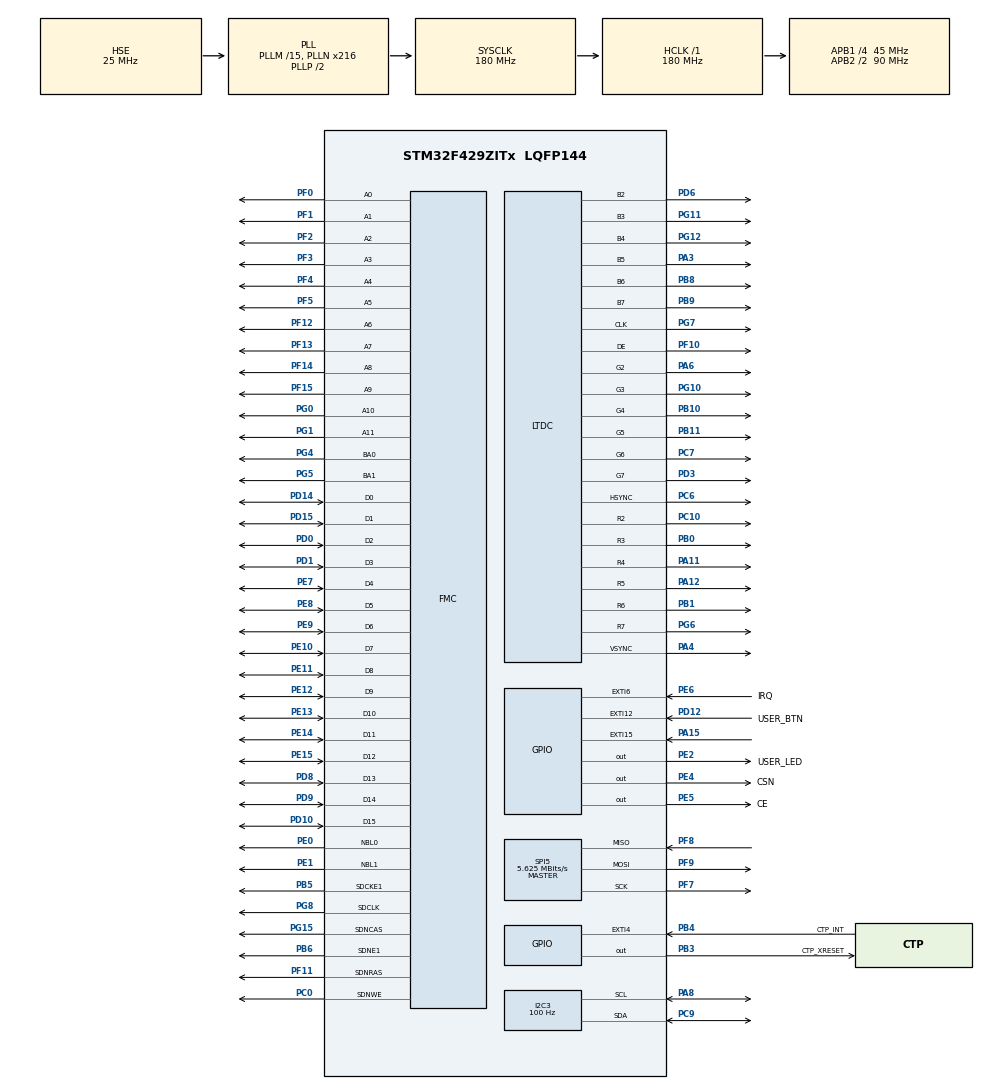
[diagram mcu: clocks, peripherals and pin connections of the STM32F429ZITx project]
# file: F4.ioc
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STMicroelectronics.X-CUBE-TOUCHGFX.4.14.0.tgfx_address1=0xd0000000
SH.FMC_D7_DA7.0=FMC_D7,sd-16b-d1
STMicroelectronics.X-CUBE-TOUCHGFX.4.14.0.tgfx_address2=0xC003FC00
PD12.GPIO_Label=USER_BTN
VP_SYS_VS_tim6.Mode=TIM6
FMC.RCDDelay1=2
FMC.SDClockPeriod1=FMC_SDRAM_CLOCK_PERIOD_2
SH.FMC_A0.0=FMC_A0,12b-sda1
PB10.Mode=RGB666
VP_ADC1_TempSens_Input.Mode=IN-TempSens
FREERTOS.configUSE_DAEMON_TASK_STARTUP_HOOK=0
NVIC.TIM6_DAC_IRQn=true\:0\:0\:false\:false\:true\:false\:true\:true
PG8.Signal=FMC_SDCLK
PG4.Signal=FMC_A14_BA0
PG0.Signal=FMC_A10
FMC.LoadToActiveDelay1=2
SH.FMC_D5_DA5.0=FMC_D5,sd-16b-d1
PG6.Mode=RGB666
PE6.GPIO_Label=IRQ
LTDC.Red=0
RCC.SYSCLKSource=RCC_SYSCLKSOURCE_PLLCLK
SH.FMC_A15_BA1.0=FMC_BA1,FourSdramBanks1
SH.FMC_D9_DA9.0=FMC_D9,sd-16b-d1
FREERTOS.configENABLE_FPU=0
FREERTOS.INCLUDE_pcTaskGetTaskName=0
I2C3.AddressingMode=I2C_ADDRESSINGMODE_7BIT
PA4.Mode=RGB666
PF7.Signal=SPI5_SCK
NVIC.DMA2D_IRQn=true\:5\:0\:true\:false\:true\:true\:true\:true
SH.FMC_SDNWE.0=FMC_SDNWE,12b-sda1
PB3.PinState=GPIO_PIN_SET
SH.FMC_D11_DA11.0=FMC_D11,sd-16b-d1
RCC.APB2TimFreq_Value=180000000
PB6.Signal=FMC_SDNE1
PC7.Signal=LTDC_G6
PH1/OSC_OUT.Signal=RCC_OSC_OUT
PB6.Mode=SdramChipSelect2_1
PD0.Signal=FMC_D2_DA2
PD8.Signal=FMC_D13_DA13
PE5.Signal=GPIO_Output
PE1.Signal=FMC_NBL1
FREERTOS.configMINIMAL_STACK_SIZE=128
I2C3.Analog_Filter=I2C_ANALOGFILTER_ENABLE
NVIC.EXTI15_10_IRQn=true\:0\:0\:false\:false\:true\:true\:true\:true
FMC.SelfRefreshTime1=4
LTDC.PixelFormat_L0=LTDC_PIXEL_FORMAT_RGB565
FREERTOS.INCLUDE_xQueueGetMutexHolder=0
PE9.Signal=FMC_D6_DA6
SH.FMC_A2.0=FMC_A2,12b-sda1
FREERTOS.HEAP_NUMBER=4
PE4.GPIO_Label=CSN
PC9.Mode=I2C
PE2.Signal=GPIO_Output
PF8.Mode=Full_Duplex_Master
PA8.Signal=I2C3_SCL
SH.FMC_D1_DA1.0=FMC_D1,sd-16b-d1
PF3.Signal=FMC_A3
VP_FREERTOS_VS_CMSIS_V1.Mode=CMSIS_V1
FMC.WriteProtection1=FMC_SDRAM_WRITE_PROTECTION_DISABLE
PD3.Mode=RGB666
PE10.Signal=FMC_D7_DA7
LTDC.HSync=1
ADC1.SamplingTime-0\#ChannelRegularConversion=ADC_SAMPLETIME_56CYCLES
Mcu.Package=LQFP144
PB9.Signal=LTDC_B7
PB1.Signal=LTDC_R6
FREERTOS.configUSE_NEWLIB_REENTRANT=0
NVIC.TimeBase=TIM6_DAC_IRQn
FREERTOS.INCLUDE_vTaskSuspend=1
PD12.Signal=GPXTI12
I2C3.NoStretchMode=I2C_NOSTRETCH_DISABLE
STMicroelectronics.X-CUBE-TOUCHGFX.4.14.0.tgfx_vsync=vsync_ltdc
LTDC.Green=0
NVIC.TimeBaseIP=TIM6
FREERTOS.copyHeapFile=1
FMC.WriteRecoveryTime1=3
SH.FMC_A1.0=FMC_A1,12b-sda1
FREERTOS.INCLUDE_vTaskPrioritySet=1
SPI5.CalculateBaudRate=5.625 MBits/s
RCC.APB2CLKDivider=RCC_HCLK_DIV2
SH.FMC_SDCLK.0=FMC_SDCLK,12b-sda1
LTDC.VSync=5
PF14.Signal=FMC_A8
RCC.APB1TimFreq_Value=90000000
FREERTOS.configGENERATE_RUN_TIME_STATS=0
VP_DMA2D_VS_DMA2D.Mode=DMA2D_Activate
PF10.Mode=RGB666
FMC.RowCycleDelay1=7
PD15.Signal=FMC_D1_DA1
SH.FMC_D3_DA3.0=FMC_D3,sd-16b-d1
SPI5.VirtualType=VM_MASTER
PG12.Signal=LTDC_B4
STMicroelectronics.X-CUBE-TOUCHGFX.4.14.0.tgfx_display_interface=disp_ltdc
NVIC.EXTI4_IRQn=true\:0\:0\:false\:false\:true\:false\:true\:true
SH.FMC_A4.0=FMC_A4,12b-sda1
FREERTOS.configIDLE_SHOULD_YIELD=1
FREERTOS.Tasks01=defaultTask,0,4096,StartDefaultTask,Default,NULL,Dynamic,NULL,NULL;ComunicationTas,0,128,StartComunicationTask,Default,NULL,Dynamic,NULL,NULL
ADC1.Rank-0\#ChannelRegularConversion=1
I2C3.OwnAddress=0
FREERTOS.INCLUDE_xTaskGetCurrentTaskHandle=0
DMA2D.AlphaModeForeground=DMA2D_NO_MODIF_ALPHA
PG5.Signal=FMC_A15_BA1
FREERTOS.configLIBRARY_LOWEST_INTERRUPT_PRIORITY=15
SH.FMC_D10_DA10.0=FMC_D10,sd-16b-d1
FREERTOS.INCLUDE_vTaskDelayUntil=0
FREERTOS.configCHECK_FOR_STACK_OVERFLOW=2
PD3.Signal=LTDC_G7
PC6.Signal=LTDC_HSYNC
PD1.Signal=FMC_D3_DA3
PC0.Signal=FMC_SDNWE
RCC.APB1CLKDivider=RCC_HCLK_DIV4
PD6.Mode=RGB666
PG10.Signal=LTDC_G3
DMA2D.InputOffsetForeground=0
LTDC.ImageWidth_L0=480
PD10.Signal=FMC_D15_DA15
PA3.Mode=RGB666
SH.FMC_A3.0=FMC_A3,12b-sda1
FMC.CASLatency1=FMC_SDRAM_CAS_LATENCY_3
PB11.Mode=RGB666
FREERTOS.configMAX_PRIORITIES=7
SH.FMC_D15_DA15.0=FMC_D15,sd-16b-d1
PC6.Mode=RGB666
FMC.SDBank1=FMC_SDRAM_BANK2
PB10.Signal=LTDC_G4
FREERTOS.configUSE_POSIX_ERRNO=0
FREERTOS.MEMORY_ALLOCATION=2
FMC.ReadBurst1=FMC_SDRAM_RBURST_DISABLE
SH.FMC_A6.0=FMC_A6,12b-sda1
PE14.Signal=FMC_D11_DA11
LTDC.Blue_L0=0
PE15.Signal=FMC_D12_DA12
PB4.GPIO_Label=CTP_INT
PE8.Signal=FMC_D5_DA5
I2C3.DualAddressMode=I2C_DUALADDRESS_DISABLE
FREERTOS.configUSE_CO_ROUTINES=0
FREERTOS.configUSE_MUTEXES=1
FREERTOS.INCLUDE_xEventGroupSetBitFromISR=0
PF13.Signal=FMC_A7
FREERTOS.configMAX_CO_ROUTINE_PRIORITIES=2
PA13.Mode=Serial_Wire
SH.FMC_SDNCAS.0=FMC_SDNCAS,12b-sda1
FREERTOS.INCLUDE_xTaskResumeFromISR=1
STMicroelectronics.X-CUBE-TOUCHGFX.4.14.0.tgfx_hardware_accelerator=dma_2d
FREERTOS.INCLUDE_uxTaskGetStackHighWaterMark2=0
PA4.Signal=LTDC_VSYNC
FREERTOS.configLIBRARY_MAX_SYSCALL_INTERRUPT_PRIORITY=5
PB5.Signal=FMC_SDCKE1
ADC1.master=1
FREERTOS.configUSE_COUNTING_SEMAPHORES=1
PE5.GPIO_Label=CE
SH.FMC_A5.0=FMC_A5,12b-sda1
PG11.Mode=RGB666
LTDC.Alpha_L0=255
PA11.Signal=LTDC_R4
ProjectManager.HeapSize=0x200
PB1.Mode=RGB666
FREERTOS.configUSE_RECURSIVE_MUTEXES=1
PF9.Signal=SPI5_MOSI
NVIC.PriorityGroup=NVIC_PRIORITYGROUP_4
PB8.Mode=RGB666
NVIC.I2C3_ER_IRQn=true\:5\:0\:true\:false\:true\:false\:true\:true
PA8.Mode=I2C
PF4.Signal=FMC_A4
PB0.Signal=LTDC_R3
LTDC.Alpha0_L0=0
Mcu.Family=STM32F4
STMicroelectronics.X-CUBE-TOUCHGFX.4.14.0.ApplicationCcGraphicsJjApplication=TouchGFXOoGenerator
LTDC.BlendingFactor1_L0=LTDC_BLENDING_FACTOR1_CA
PA6.Mode=RGB666
SH.FMC_A8.0=FMC_A8,12b-sda1
RCC.CortexFreq_Value=180000000
PG6.Signal=LTDC_R7
SH.FMC_D14_DA14.0=FMC_D14,sd-16b-d1
LTDC.HBP=42
PC10.Signal=LTDC_R2
SH.FMC_NBL0.0=FMC_NBL0,Sd2ByteEnable1
SH.FMC_D6_DA6.0=FMC_D6,sd-16b-d1
PA11.Mode=RGB666
FREERTOS.configTICK_RATE_HZ=1000
SH.FMC_A14_BA0.0=FMC_BA0,FourSdramBanks1
SH.FMC_A11.0=FMC_A11,12b-sda1
PB11.Signal=LTDC_G5
FREERTOS.configUSE_TASK_NOTIFICATIONS=1
LTDC.PCPolarity=LTDC_PCPOLARITY_IPC
VP_STMicroelectronics.X-CUBE-TOUCHGFX_VS_GraphicsJjApplication_4.14.0.Mode=GraphicsJjApplication
PG11.Signal=LTDC_B3
PG15.Signal=FMC_SDNCAS
ProjectManager.StackSize=0x400
STMicroelectronics.X-CUBE-TOUCHGFX.4.14.0.tgfx_buffering_strategy=Single
SH.FMC_A7.0=FMC_A7,12b-sda1
PA12.Signal=LTDC_R5
LTDC.Blue=0
FREERTOS.configUSE_STATS_FORMATTING_FUNCTIONS=0
PH0/OSC_IN.Mode=HSE-External-Oscillator
RCC.HCLKFreq_Value=180000000
SH.FMC_NBL1.0=FMC_NBL1,Sd2ByteEnable1
LTDC.WindowX1_L0=480
PF12.Signal=FMC_A6
FREERTOS.configUSE_MALLOC_FAILED_HOOK=1
FREERTOS.configQUEUE_REGISTRY_SIZE=8
SH.FMC_A10.0=FMC_A10,12b-sda1
RCC.AHBFreq_Value=180000000
FREERTOS.configUSE_PREEMPTION=1
ADC1.Channel-0\#ChannelRegularConversion=ADC_CHANNEL_TEMPSENSOR
RCC.HSE_VALUE=25000000
FREERTOS.configUSE_TIMERS=0
SH.FMC_D8_DA8.0=FMC_D8,sd-16b-d1
FMC.ExitSelfRefreshDelay1=7
FMC.RPDelay1=2
FREERTOS.configENABLE_BACKWARD_COMPATIBILITY=1
SH.FMC_D2_DA2.0=FMC_D2,sd-16b-d1
LTDC.VBP=10
NVIC.I2C3_EV_IRQn=true\:5\:0\:true\:false\:true\:false\:true\:true
PF9.Mode=Full_Duplex_Master
PE13.Signal=FMC_D10_DA10
PA14.Mode=Serial_Wire
PF11.Signal=FMC_SDNRAS
PB5.Mode=SdramChipSelect2_1
DMA2D.BytesSwap=DMA2D_BYTES_REGULAR
LTDC.Red_L0=0
LTDC.HFP=8
LTDC.BlendingFactor2_L0=LTDC_BLENDING_FACTOR2_CA
FREERTOS.INCLUDE_vTaskCleanUpResources=0
FMC.ReadPipeDelay1=FMC_SDRAM_RPIPE_DELAY_1
FMC.ReadPipeDelay2=FMC_SDRAM_RPIPE_DELAY_1
DMA2D.InputColorModeForeground=DMA2D_INPUT_ARGB8888
SH.FMC_SDNRAS.0=FMC_SDNRAS,12b-sda1
DMA2D.ColorMode=DMA2D_OUTPUT_ARGB8888
LTDC.ActiveW=480
PH1/OSC_OUT.Mode=HSE-External-Oscillator
PE4.Signal=GPIO_Output
FREERTOS.configTOTAL_HEAP_SIZE=32768
DMA2D.InputAlphaForeground=0
SPI5.BaudRatePrescaler=SPI_BAUDRATEPRESCALER_16
PA6.Signal=LTDC_G2
FREERTOS.INCLUDE_xTaskAbortDelay=0
SH.FMC_D0_DA0.0=FMC_D0,sd-16b-d1
DMA2D.OutputOffset=0
SH.FMC_A9.0=FMC_A9,12b-sda1
PA15.Signal=GPXTI15
PF8.Signal=SPI5_MISO
SH.FMC_D4_DA4.0=FMC_D4,sd-16b-d1
RCC.PLLSAIN=60
PF5.Signal=FMC_A5
FREERTOS.configUSE_TICK_HOOK=0
PF0.Signal=FMC_A0
LTDC.VSPolarity=LTDC_VSPOLARITY_AL
PE7.Signal=FMC_D4_DA4
FREERTOS.configMAX_TASK_NAME_LEN=16
PD6.Signal=LTDC_B2
PE2.GPIO_Label=USER_LED
DMA2D.LineOffsetMode=DMA2D_LOM_PIXELS
PB4.Signal=GPXTI4
PA3.Signal=LTDC_B5
PB3.GPIO_Label=CTP_XRESET
RCC.PLLSourceVirtual=RCC_PLLSOURCE_HSE
I2C3.I2C_Mode=I2C_Standard
NVIC.LTDC_IRQn=true\:5\:0\:true\:false\:true\:true\:true\:true
LTDC.FBStartAdress_L0=0xd0000000
LTDC.VFP=1
LTDC.HSPolarity=LTDC_HSPOLARITY_AL
STMicroelectronics.X-CUBE-TOUCHGFX.4.14.0.tgfx_location=By Address
LTDC.WindowY1_L0=272
PG7.Signal=LTDC_CLK
PG1.Signal=FMC_A11
FREERTOS.configUSE_TICKLESS_IDLE=0
I2C3.ClockSpeed=100
PC10.Mode=RGB666
PG10.Mode=RGB666
PD9.Signal=FMC_D14_DA14
FREERTOS.INCLUDE_vTaskDelay=1
FREERTOS.configUSE_APPLICATION_TASK_TAG=1
SPI5.Mode=SPI_MODE_MASTER
FREERTOS.INCLUDE_uxTaskGetStackHighWaterMark=0
PA13.Signal=SYS_JTMS-SWDIO
FREERTOS.configUSE_IDLE_HOOK=1
PF7.Mode=Full_Duplex_Master
FREERTOS.INCLUDE_vTaskDelete=1
I2C3.GeneralCallMode=I2C_GENERALCALL_DISABLE
I2C3.I2C_Coeff_DF=0
FREERTOS.configRECORD_STACK_HIGH_ADDRESS=0
ProjectManager.TargetToolchain=STM32CubeIDE
FREERTOS.configUSE_TRACE_FACILITY=0
SH.FMC_D13_DA13.0=FMC_D13,sd-16b-d1
LTDC.ActiveH=272
PB9.Mode=RGB666
PF2.Signal=FMC_A2
PE11.Signal=FMC_D8_DA8
PG7.Mode=RGB666
PB0.Mode=RGB666
board=custom
PG12.Mode=RGB666
RCC.VCOOutputFreq_Value=360000000
FREERTOS.INCLUDE_eTaskGetState=0
PH0/OSC_IN.Signal=RCC_OSC_IN
RCC.APB2Freq_Value=90000000
LTDC.Layers=0
PF10.Signal=LTDC_DE
SH.FMC_D12_DA12.0=FMC_D12,sd-16b-d1
PF15.Signal=FMC_A9
PF1.Signal=FMC_A1
PE6.Signal=GPXTI6
FREERTOS.INCLUDE_uxTaskPriorityGet=1
Mcu.Name=STM32F429ZITx
PE0.Signal=FMC_NBL0
PE12.Signal=FMC_D9_DA9
FREERTOS.INCLUDE_xSemaphoreGetMutexHolder=0
PD14.Signal=FMC_D0_DA0
LTDC.WindowY0_L0=0
RCC.48MHZClocksFreq_Value=90000000
PB3.Signal=GPIO_Output
RCC.SYSCLKFreq_VALUE=180000000
PA12.Mode=RGB666
LTDC.WindowX0_L0=0
LTDC.Green_L0=0
PA14.Signal=SYS_JTCK-SWCLK
FREERTOS.INCLUDE_xTaskGetHandle=0
LTDC.DEPolarity=LTDC_DEPOLARITY_AL
RCC.HSI_VALUE=16000000
ADC1.NbrOfConversionFlag=1
RCC.PLLM=15
RCC.PLLN=216
PB8.Signal=LTDC_B6
PC9.Signal=I2C3_SDA
PC7.Mode=RGB666
RCC.APB1Freq_Value=45000000
VP_CRC_VS_CRC.Mode=CRC_Activate
LTDC.ImageHeight_L0=272
DMA2D.Mode=DMA2D_M2M
SPI5.Direction=SPI_DIRECTION_2LINES

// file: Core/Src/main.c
/* USER CODE BEGIN Header */
/**
  ******************************************************************************
  * @file           : main.c
  * @brief          : Main program body
  ******************************************************************************
  * @attention
  *
  * <h2><center>&copy; Copyright (c) 2020 STMicroelectronics.
  * All rights reserved.</center></h2>
  *
  * This software component is licensed by ST under Ultimate Liberty license
  * SLA0044, the "License"; You may not use this file except in compliance with
  * the License. You may obtain a copy of the License at:
  *                             www.st.com/SLA0044
  *
  ******************************************************************************
  */
/* USER CODE END Header */
#include "main.h"
#include "cmsis_os.h"
#include "app_touchgfx.h"

/* USER CODE BEGIN Includes */
#include "FreeRTOS.h"
#include "queue.h"
#include "task.h"
#include "nRF24.h"
#include "nRF24_Defs.h"
/* USER CODE END Includes */

/* USER CODE BEGIN PD */
#define REFRESH_COUNT        1386

#define SDRAM_TIMEOUT                            ((uint32_t)0xFFFF)
#define SDRAM_MODEREG_BURST_LENGTH_1             ((uint16_t)0x0000)
#define SDRAM_MODEREG_BURST_LENGTH_2             ((uint16_t)0x0001)
#define SDRAM_MODEREG_BURST_LENGTH_4             ((uint16_t)0x0002)
#define SDRAM_MODEREG_BURST_LENGTH_8             ((uint16_t)0x0004)
#define SDRAM_MODEREG_BURST_TYPE_SEQUENTIAL      ((uint16_t)0x0000)
#define SDRAM_MODEREG_BURST_TYPE_INTERLEAVED     ((uint16_t)0x0008)
#define SDRAM_MODEREG_CAS_LATENCY_2              ((uint16_t)0x0020)
#define SDRAM_MODEREG_CAS_LATENCY_3              ((uint16_t)0x0030)
#define SDRAM_MODEREG_OPERATING_MODE_STANDARD    ((uint16_t)0x0000)
#define SDRAM_MODEREG_WRITEBURST_MODE_PROGRAMMED ((uint16_t)0x0000)
#define SDRAM_MODEREG_WRITEBURST_MODE_SINGLE     ((uint16_t)0x0200)

static FMC_SDRAM_CommandTypeDef Command;
/* USER CODE END PD */

ADC_HandleTypeDef hadc1;

CRC_HandleTypeDef hcrc;

DMA2D_HandleTypeDef hdma2d;

I2C_HandleTypeDef hi2c3;

LTDC_HandleTypeDef hltdc;

SPI_HandleTypeDef hspi5;

SDRAM_HandleTypeDef hsdram1;

osThreadId defaultTaskHandle;
osThreadId ComunicationTasHandle;
/* USER CODE BEGIN PV */
volatile uint8_t nrf24_rx_flag, nrf24_tx_flag, nrf24_mr_flag;
uint8_t Nrf24_Message[NRF24_PAYLOAD_SIZE];
uint8_t Message[32];
uint8_t MessageLength;
/* USER CODE END PV */

void SystemClock_Config(void);
static void MX_GPIO_Init(void);
static void MX_LTDC_Init(void);
static void MX_CRC_Init(void);
static void MX_DMA2D_Init(void);
static void MX_FMC_Init(void);
static void MX_I2C3_Init(void);
static void MX_ADC1_Init(void);
static void MX_SPI5_Init(void);
void StartDefaultTask(void const * argument);
void StartComunicationTask(void const * argument);

int main(void)
{

  /* MCU Configuration--------------------------------------------------------*/

  /* Reset of all peripherals, Initializes the Flash interface and the Systick. */
  HAL_Init();

  /* Configure the system clock */
  SystemClock_Config();

  /* Initialize all configured peripherals */
  MX_GPIO_Init();
  MX_LTDC_Init();
  MX_CRC_Init();
  MX_DMA2D_Init();
  MX_FMC_Init();
  MX_I2C3_Init();
  MX_TouchGFX_Init();
  MX_ADC1_Init();
  MX_SPI5_Init();
  //MX_TouchGFX_Init();
  /* USER CODE BEGIN 2 */
  //nRF24_Init(&hspi5);
  //nRF24_SetRXAddress(0, "TX");
  //nRF24_SetTXAddress("RX");
  //nRF24_RX_Mode();
  /* USER CODE END 2 */

  /* Create the thread(s) */
  /* definition and creation of defaultTask */
  osThreadDef(defaultTask, StartDefaultTask, osPriorityNormal, 0, 4096);
  defaultTaskHandle = osThreadCreate(osThread(defaultTask), NULL);

  /* definition and creation of ComunicationTas */
  osThreadDef(ComunicationTas, StartComunicationTask, osPriorityNormal, 0, 128);
  ComunicationTasHandle = osThreadCreate(osThread(ComunicationTas), NULL);

  /* Start scheduler */
  osKernelStart();

  /* We should never get here as control is now taken by the scheduler */
  /* Infinite loop */
  while (1)
  {

  }
}

void SystemClock_Config(void)
{
  RCC_OscInitTypeDef RCC_OscInitStruct = {0};
  RCC_ClkInitTypeDef RCC_ClkInitStruct = {0};
  RCC_PeriphCLKInitTypeDef PeriphClkInitStruct = {0};

  /** Configure the main internal regulator output voltage
  */
  __HAL_RCC_PWR_CLK_ENABLE();
  __HAL_PWR_VOLTAGESCALING_CONFIG(PWR_REGULATOR_VOLTAGE_SCALE1);
  /** Initializes the RCC Oscillators according to the specified parameters
  * in the RCC_OscInitTypeDef structure.
  */
  RCC_OscInitStruct.OscillatorType = RCC_OSCILLATORTYPE_HSE;
  RCC_OscInitStruct.HSEState = RCC_HSE_ON;
  RCC_OscInitStruct.PLL.PLLState = RCC_PLL_ON;
  RCC_OscInitStruct.PLL.PLLSource = RCC_PLLSOURCE_HSE;
  RCC_OscInitStruct.PLL.PLLM = 15;
  RCC_OscInitStruct.PLL.PLLN = 216;
  RCC_OscInitStruct.PLL.PLLP = RCC_PLLP_DIV2;
  RCC_OscInitStruct.PLL.PLLQ = 4;
  if (HAL_RCC_OscConfig(&RCC_OscInitStruct) != HAL_OK)
  {
    Error_Handler();
  }
  /** Activate the Over-Drive mode
  */
  if (HAL_PWREx_EnableOverDrive() != HAL_OK)
  {
    Error_Handler();
  }
  /** Initializes the CPU, AHB and APB buses clocks
  */
  RCC_ClkInitStruct.ClockType = RCC_CLOCKTYPE_HCLK|RCC_CLOCKTYPE_SYSCLK
                              |RCC_CLOCKTYPE_PCLK1|RCC_CLOCKTYPE_PCLK2;
  RCC_ClkInitStruct.SYSCLKSource = RCC_SYSCLKSOURCE_PLLCLK;
  RCC_ClkInitStruct.AHBCLKDivider = RCC_SYSCLK_DIV1;
  RCC_ClkInitStruct.APB1CLKDivider = RCC_HCLK_DIV4;
  RCC_ClkInitStruct.APB2CLKDivider = RCC_HCLK_DIV2;

  if (HAL_RCC_ClockConfig(&RCC_ClkInitStruct, FLASH_LATENCY_5) != HAL_OK)
  {
    Error_Handler();
  }
  PeriphClkInitStruct.PeriphClockSelection = RCC_PERIPHCLK_LTDC;
  PeriphClkInitStruct.PLLSAI.PLLSAIN = 60;
  PeriphClkInitStruct.PLLSAI.PLLSAIR = 2;
  PeriphClkInitStruct.PLLSAIDivR = RCC_PLLSAIDIVR_2;
  if (HAL_RCCEx_PeriphCLKConfig(&PeriphClkInitStruct) != HAL_OK)
  {
    Error_Handler();
  }
}

static void MX_ADC1_Init(void)
{

  ADC_ChannelConfTypeDef sConfig = {0};

  /** Configure the global features of the ADC (Clock, Resolution, Data Alignment and number of conversion)
  */
  hadc1.Instance = ADC1;
  hadc1.Init.ClockPrescaler = ADC_CLOCK_SYNC_PCLK_DIV4;
  hadc1.Init.Resolution = ADC_RESOLUTION_12B;
  hadc1.Init.ScanConvMode = DISABLE;
  hadc1.Init.ContinuousConvMode = DISABLE;
  hadc1.Init.DiscontinuousConvMode = DISABLE;
  hadc1.Init.ExternalTrigConvEdge = ADC_EXTERNALTRIGCONVEDGE_NONE;
  hadc1.Init.ExternalTrigConv = ADC_SOFTWARE_START;
  hadc1.Init.DataAlign = ADC_DATAALIGN_RIGHT;
  hadc1.Init.NbrOfConversion = 1;
  hadc1.Init.DMAContinuousRequests = DISABLE;
  hadc1.Init.EOCSelection = ADC_EOC_SINGLE_CONV;
  if (HAL_ADC_Init(&hadc1) != HAL_OK)
  {
    Error_Handler();
  }
  /** Configure for the selected ADC regular channel its corresponding rank in the sequencer and its sample time.
  */
  sConfig.Channel = ADC_CHANNEL_TEMPSENSOR;
  sConfig.Rank = 1;
  sConfig.SamplingTime = ADC_SAMPLETIME_56CYCLES;
  if (HAL_ADC_ConfigChannel(&hadc1, &sConfig) != HAL_OK)
  {
    Error_Handler();
  }

}

static void MX_CRC_Init(void)
{

  hcrc.Instance = CRC;
  if (HAL_CRC_Init(&hcrc) != HAL_OK)
  {
    Error_Handler();
  }

}

static void MX_DMA2D_Init(void)
{

  hdma2d.Instance = DMA2D;
  hdma2d.Init.Mode = DMA2D_M2M;
  hdma2d.Init.ColorMode = DMA2D_OUTPUT_ARGB8888;
  hdma2d.Init.OutputOffset = 0;
  hdma2d.LayerCfg[1].InputOffset = 0;
  hdma2d.LayerCfg[1].InputColorMode = DMA2D_INPUT_ARGB8888;
  hdma2d.LayerCfg[1].AlphaMode = DMA2D_NO_MODIF_ALPHA;
  hdma2d.LayerCfg[1].InputAlpha = 0;
  if (HAL_DMA2D_Init(&hdma2d) != HAL_OK)
  {
    Error_Handler();
  }
  if (HAL_DMA2D_ConfigLayer(&hdma2d, 1) != HAL_OK)
  {
    Error_Handler();
  }

}

static void MX_I2C3_Init(void)
{

  hi2c3.Instance = I2C3;
  hi2c3.Init.ClockSpeed = 100;
  hi2c3.Init.DutyCycle = I2C_DUTYCYCLE_2;
  hi2c3.Init.OwnAddress1 = 0;
  hi2c3.Init.AddressingMode = I2C_ADDRESSINGMODE_7BIT;
  hi2c3.Init.DualAddressMode = I2C_DUALADDRESS_DISABLE;
  hi2c3.Init.OwnAddress2 = 0;
  hi2c3.Init.GeneralCallMode = I2C_GENERALCALL_DISABLE;
  hi2c3.Init.NoStretchMode = I2C_NOSTRETCH_DISABLE;
  if (HAL_I2C_Init(&hi2c3) != HAL_OK)
  {
    Error_Handler();
  }
  /** Configure Analogue filter
  */
  if (HAL_I2CEx_ConfigAnalogFilter(&hi2c3, I2C_ANALOGFILTER_ENABLE) != HAL_OK)
  {
    Error_Handler();
  }
  /** Configure Digital filter
  */
  if (HAL_I2CEx_ConfigDigitalFilter(&hi2c3, 0) != HAL_OK)
  {
    Error_Handler();
  }

}

static void MX_LTDC_Init(void)
{

  LTDC_LayerCfgTypeDef pLayerCfg = {0};
  LTDC_LayerCfgTypeDef pLayerCfg1 = {0};

  hltdc.Instance = LTDC;
  hltdc.Init.HSPolarity = LTDC_HSPOLARITY_AL;
  hltdc.Init.VSPolarity = LTDC_VSPOLARITY_AL;
  hltdc.Init.DEPolarity = LTDC_DEPOLARITY_AL;
  hltdc.Init.PCPolarity = LTDC_PCPOLARITY_IPC;
  hltdc.Init.HorizontalSync = 0;
  hltdc.Init.VerticalSync = 4;
  hltdc.Init.AccumulatedHBP = 42;
  hltdc.Init.AccumulatedVBP = 14;
  hltdc.Init.AccumulatedActiveW = 522;
  hltdc.Init.AccumulatedActiveH = 286;
  hltdc.Init.TotalWidth = 530;
  hltdc.Init.TotalHeigh = 287;
  hltdc.Init.Backcolor.Blue = 0;
  hltdc.Init.Backcolor.Green = 0;
  hltdc.Init.Backcolor.Red = 0;
  if (HAL_LTDC_Init(&hltdc) != HAL_OK)
  {
    Error_Handler();
  }
  pLayerCfg.WindowX0 = 0;
  pLayerCfg.WindowX1 = 480;
  pLayerCfg.WindowY0 = 0;
  pLayerCfg.WindowY1 = 272;
  pLayerCfg.PixelFormat = LTDC_PIXEL_FORMAT_RGB565;
  pLayerCfg.Alpha = 255;
  pLayerCfg.Alpha0 = 0;
  pLayerCfg.BlendingFactor1 = LTDC_BLENDING_FACTOR1_CA;
  pLayerCfg.BlendingFactor2 = LTDC_BLENDING_FACTOR2_CA;
  pLayerCfg.FBStartAdress = 0xd0000000;
  pLayerCfg.ImageWidth = 480;
  pLayerCfg.ImageHeight = 272;
  pLayerCfg.Backcolor.Blue = 0;
  pLayerCfg.Backcolor.Green = 0;
  pLayerCfg.Backcolor.Red = 0;
  if (HAL_LTDC_ConfigLayer(&hltdc, &pLayerCfg, 0) != HAL_OK)
  {
    Error_Handler();
  }
  pLayerCfg1.WindowX0 = 0;
  pLayerCfg1.WindowX1 = 0;
  pLayerCfg1.WindowY0 = 0;
  pLayerCfg1.WindowY1 = 0;
  pLayerCfg1.Alpha = 0;
  pLayerCfg1.Alpha0 = 0;
  pLayerCfg1.BlendingFactor1 = LTDC_BLENDING_FACTOR1_CA;
  pLayerCfg1.BlendingFactor2 = LTDC_BLENDING_FACTOR2_CA;
  pLayerCfg1.FBStartAdress = 0;
  pLayerCfg1.ImageWidth = 0;
  pLayerCfg1.ImageHeight = 0;
  pLayerCfg1.Backcolor.Blue = 0;
  pLayerCfg1.Backcolor.Green = 0;
  pLayerCfg1.Backcolor.Red = 0;
  if (HAL_LTDC_ConfigLayer(&hltdc, &pLayerCfg1, 1) != HAL_OK)
  {
    Error_Handler();
  }

}

static void MX_SPI5_Init(void)
{

  /* SPI5 parameter configuration*/
  hspi5.Instance = SPI5;
  hspi5.Init.Mode = SPI_MODE_MASTER;
  hspi5.Init.Direction = SPI_DIRECTION_2LINES;
  hspi5.Init.DataSize = SPI_DATASIZE_8BIT;
  hspi5.Init.CLKPolarity = SPI_POLARITY_LOW;
  hspi5.Init.CLKPhase = SPI_PHASE_1EDGE;
  hspi5.Init.NSS = SPI_NSS_SOFT;
  hspi5.Init.BaudRatePrescaler = SPI_BAUDRATEPRESCALER_16;
  hspi5.Init.FirstBit = SPI_FIRSTBIT_MSB;
  hspi5.Init.TIMode = SPI_TIMODE_DISABLE;
  hspi5.Init.CRCCalculation = SPI_CRCCALCULATION_DISABLE;
  hspi5.Init.CRCPolynomial = 10;
  if (HAL_SPI_Init(&hspi5) != HAL_OK)
  {
    Error_Handler();
  }

}

/* FMC initialization function */
static void MX_FMC_Init(void)
{

  FMC_SDRAM_TimingTypeDef SdramTiming = {0};

  /** Perform the SDRAM1 memory initialization sequence
  */
  hsdram1.Instance = FMC_SDRAM_DEVICE;
  /* hsdram1.Init */
  hsdram1.Init.SDBank = FMC_SDRAM_BANK2;
  hsdram1.Init.ColumnBitsNumber = FMC_SDRAM_COLUMN_BITS_NUM_8;
  hsdram1.Init.RowBitsNumber = FMC_SDRAM_ROW_BITS_NUM_12;
  hsdram1.Init.MemoryDataWidth = FMC_SDRAM_MEM_BUS_WIDTH_16;
  hsdram1.Init.InternalBankNumber = FMC_SDRAM_INTERN_BANKS_NUM_4;
  hsdram1.Init.CASLatency = FMC_SDRAM_CAS_LATENCY_3;
  hsdram1.Init.WriteProtection = FMC_SDRAM_WRITE_PROTECTION_DISABLE;
  hsdram1.Init.SDClockPeriod = FMC_SDRAM_CLOCK_PERIOD_2;
  hsdram1.Init.ReadBurst = FMC_SDRAM_RBURST_DISABLE;
  hsdram1.Init.ReadPipeDelay = FMC_SDRAM_RPIPE_DELAY_1;
  /* SdramTiming */
  SdramTiming.LoadToActiveDelay = 2;
  SdramTiming.ExitSelfRefreshDelay = 7;
  SdramTiming.SelfRefreshTime = 4;
  SdramTiming.RowCycleDelay = 7;
  SdramTiming.WriteRecoveryTime = 3;
  SdramTiming.RPDelay = 2;
  SdramTiming.RCDDelay = 2;

  if (HAL_SDRAM_Init(&hsdram1, &SdramTiming) != HAL_OK)
  {
    Error_Handler( );
  }

  /* USER CODE BEGIN FMC_Init 2 */
  __IO uint32_t tmpmrd = 0;

    /* Step 1: Configure a clock configuration enable command */
    Command.CommandMode            = FMC_SDRAM_CMD_CLK_ENABLE;
    Command.CommandTarget          =  FMC_SDRAM_CMD_TARGET_BANK2;
    Command.AutoRefreshNumber      = 1;
    Command.ModeRegisterDefinition = 0;

    /* Send the command */
    HAL_SDRAM_SendCommand(&hsdram1, &Command, SDRAM_TIMEOUT);

    /* Step 2: Insert 100 us minimum delay */
    /* Inserted delay is equal to 1 ms due to systick time base unit (ms) */
    HAL_Delay(10);

    /* Step 3: Configure a PALL (precharge all) command */
    Command.CommandMode            = FMC_SDRAM_CMD_PALL;
    Command.CommandTarget          = FMC_SDRAM_CMD_TARGET_BANK2;
    Command.AutoRefreshNumber      = 1;
    Command.ModeRegisterDefinition = 0;

    /* Send the command */
    HAL_SDRAM_SendCommand(&hsdram1, &Command, SDRAM_TIMEOUT);

    /* Step 4: Configure an Auto Refresh command */
    Command.CommandMode            = FMC_SDRAM_CMD_AUTOREFRESH_MODE;
    Command.CommandTarget          = FMC_SDRAM_CMD_TARGET_BANK2;
    Command.AutoRefreshNumber      = 4;
    Command.ModeRegisterDefinition = 0;

    /* Send the command */
    HAL_SDRAM_SendCommand(&hsdram1, &Command, SDRAM_TIMEOUT);

    /* Step 5: Program the external memory mode register */
    tmpmrd = (uint32_t)SDRAM_MODEREG_BURST_LENGTH_2          |\
                       SDRAM_MODEREG_BURST_TYPE_SEQUENTIAL   |\
                       SDRAM_MODEREG_CAS_LATENCY_3           |\
                       SDRAM_MODEREG_OPERATING_MODE_STANDARD |\
                       SDRAM_MODEREG_WRITEBURST_MODE_SINGLE;

    Command.CommandMode            = FMC_SDRAM_CMD_LOAD_MODE;
    Command.CommandTarget          = FMC_SDRAM_CMD_TARGET_BANK2;
    Command.AutoRefreshNumber      = 1;
    Command.ModeRegisterDefinition = tmpmrd;

    /* Send the command */
    HAL_SDRAM_SendCommand(&hsdram1, &Command, SDRAM_TIMEOUT);

    /* Step 6: Set the refresh rate counter */
    /* Set the device refresh rate */
    HAL_SDRAM_ProgramRefreshRate(&hsdram1, REFRESH_COUNT);
  /* USER CODE END FMC_Init 2 */
}

static void MX_GPIO_Init(void)
{
  GPIO_InitTypeDef GPIO_InitStruct = {0};

  /* GPIO Ports Clock Enable */
  __HAL_RCC_GPIOE_CLK_ENABLE();
  __HAL_RCC_GPIOF_CLK_ENABLE();
  __HAL_RCC_GPIOH_CLK_ENABLE();
  __HAL_RCC_GPIOC_CLK_ENABLE();
  __HAL_RCC_GPIOA_CLK_ENABLE();
  __HAL_RCC_GPIOB_CLK_ENABLE();
  __HAL_RCC_GPIOG_CLK_ENABLE();
  __HAL_RCC_GPIOD_CLK_ENABLE();

  /*Configure GPIO pin Output Level */
  HAL_GPIO_WritePin(GPIOE, USER_LED_Pin|CSN_Pin|CE_Pin, GPIO_PIN_RESET);

  /*Configure GPIO pin Output Level */
  HAL_GPIO_WritePin(CTP_XRESET_GPIO_Port, CTP_XRESET_Pin, GPIO_PIN_SET);

  /*Configure GPIO pins : USER_LED_Pin CSN_Pin CE_Pin */
  GPIO_InitStruct.Pin = USER_LED_Pin|CSN_Pin|CE_Pin;
  GPIO_InitStruct.Mode = GPIO_MODE_OUTPUT_PP;
  GPIO_InitStruct.Pull = GPIO_NOPULL;
  GPIO_InitStruct.Speed = GPIO_SPEED_FREQ_LOW;
  HAL_GPIO_Init(GPIOE, &GPIO_InitStruct);

  /*Configure GPIO pin : IRQ_Pin */
  GPIO_InitStruct.Pin = IRQ_Pin;
  GPIO_InitStruct.Mode = GPIO_MODE_IT_RISING;
  GPIO_InitStruct.Pull = GPIO_NOPULL;
  HAL_GPIO_Init(IRQ_GPIO_Port, &GPIO_InitStruct);

  /*Configure GPIO pin : USER_BTN_Pin */
  GPIO_InitStruct.Pin = USER_BTN_Pin;
  GPIO_InitStruct.Mode = GPIO_MODE_IT_RISING;
  GPIO_InitStruct.Pull = GPIO_NOPULL;
  HAL_GPIO_Init(USER_BTN_GPIO_Port, &GPIO_InitStruct);

  /*Configure GPIO pin : PA15 */
  GPIO_InitStruct.Pin = GPIO_PIN_15;
  GPIO_InitStruct.Mode = GPIO_MODE_IT_RISING;
  GPIO_InitStruct.Pull = GPIO_NOPULL;
  HAL_GPIO_Init(GPIOA, &GPIO_InitStruct);

  /*Configure GPIO pin : CTP_XRESET_Pin */
  GPIO_InitStruct.Pin = CTP_XRESET_Pin;
  GPIO_InitStruct.Mode = GPIO_MODE_OUTPUT_PP;
  GPIO_InitStruct.Pull = GPIO_NOPULL;
  GPIO_InitStruct.Speed = GPIO_SPEED_FREQ_LOW;
  HAL_GPIO_Init(CTP_XRESET_GPIO_Port, &GPIO_InitStruct);

  /*Configure GPIO pin : CTP_INT_Pin */
  GPIO_InitStruct.Pin = CTP_INT_Pin;
  GPIO_InitStruct.Mode = GPIO_MODE_IT_RISING;
  GPIO_InitStruct.Pull = GPIO_NOPULL;
  HAL_GPIO_Init(CTP_INT_GPIO_Port, &GPIO_InitStruct);

  /* EXTI interrupt init*/
  HAL_NVIC_SetPriority(EXTI4_IRQn, 0, 0);
  HAL_NVIC_EnableIRQ(EXTI4_IRQn);

  HAL_NVIC_SetPriority(EXTI15_10_IRQn, 0, 0);
  HAL_NVIC_EnableIRQ(EXTI15_10_IRQn);

}

void StartDefaultTask(void const * argument)
{
  /* USER CODE BEGIN 5 */
	MX_TouchGFX_Process();
  /* Infinite loop */
  for(;;)
  {
    osDelay(1);
  }
  /* USER CODE END 5 */
}

void StartComunicationTask(void const * argument)
{
  for(;;)
  {
  }
}

extern xQueueHandle messageQ;
unsigned int val = 0;

void secondTask(void const * argument)
{

	for(;;)
	{
		xQueueSend(messageQ, &val,0);
		osDelay(1000);
		val++;
	}
}
void HAL_TIM_PeriodElapsedCallback(TIM_HandleTypeDef *htim)
{
  if (htim->Instance == TIM6) {
    HAL_IncTick();
  }
}

void Error_Handler(void)
{
}

/************************ (C) COPYRIGHT STMicroelectronics *****END OF FILE****/
